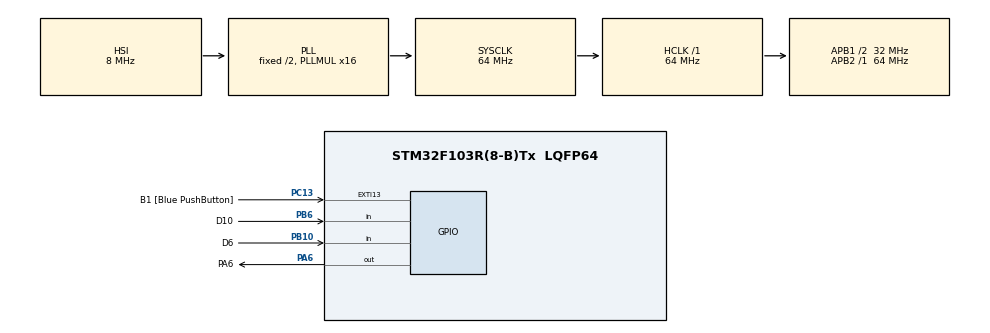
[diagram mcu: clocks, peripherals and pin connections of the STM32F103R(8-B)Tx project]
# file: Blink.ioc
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Mcu.Family=STM32F1
Mcu.Name=STM32F103R(8-B)Tx
Mcu.Package=LQFP64
NVIC.PriorityGroup=NVIC_PRIORITYGROUP_4
PA13.GPIO_Label=TMS
PA13.Mode=Serial_Wire
PA13.Signal=SYS_JTMS-SWDIO
PA14.GPIO_Label=TCK
PA14.Mode=Serial_Wire
PA14.Signal=SYS_JTCK-SWCLK
PA6.GPIO_Label=PA6
PA6.Signal=GPIO_Output
PB10.GPIO_Label=D6
PB10.GPIO_PuPd=GPIO_PULLDOWN
PB10.Signal=GPIO_Input
PB3.GPIO_Label=SWO
PB3.Signal=SYS_JTDO-TRACESWO
PB6.GPIO_Label=D10
PB6.GPIO_PuPd=GPIO_PULLDOWN
PB6.Signal=GPIO_Input
PC13-TAMPER-RTC.GPIO_Label=B1 [Blue PushButton]
PC13-TAMPER-RTC.GPIO_PuPd=GPIO_NOPULL
PC13-TAMPER-RTC.Signal=GPXTI13
PC14-OSC32_IN.Mode=LSE-External-Oscillator
PC14-OSC32_IN.Signal=RCC_OSC32_IN
PC15-OSC32_OUT.Mode=LSE-External-Oscillator
PC15-OSC32_OUT.Signal=RCC_OSC32_OUT
PD0-OSC_IN.Mode=HSE-External-Clock-Source
PD0-OSC_IN.Signal=RCC_OSC_IN
PD1-OSC_OUT.Mode=HSE-External-Clock-Source
PD1-OSC_OUT.Signal=RCC_OSC_OUT
ProjectManager.HeapSize=0x200
ProjectManager.StackSize=0x400
ProjectManager.TargetToolchain=STM32CubeIDE
RCC.AHBFreq_Value=64000000
RCC.APB1CLKDivider=RCC_HCLK_DIV2
RCC.APB1Freq_Value=32000000
RCC.APB1TimFreq_Value=64000000
RCC.APB2Freq_Value=64000000
RCC.APB2TimFreq_Value=64000000
RCC.HCLKFreq_Value=64000000
RCC.PLLMUL=RCC_PLL_MUL16
RCC.RTCClockSelection=RCC_RTCCLKSOURCE_LSE
RCC.SYSCLKFreq_VALUE=64000000
RCC.SYSCLKSource=RCC_SYSCLKSOURCE_PLLCLK
RCC.USBFreq_Value=64000000
board=NUCLEO-F103RB

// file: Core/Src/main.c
/* USER CODE BEGIN Header */
/**
 ******************************************************************************
 * @file           : main.c
 * @brief          : Main program body
 ******************************************************************************
 * @attention
 *
 * Copyright (c) 2026 STMicroelectronics.
 * All rights reserved.
 *
 * This software is licensed under terms that can be found in the LICENSE file
 * in the root directory of this software component.
 * If no LICENSE file comes with this software, it is provided AS-IS.
 *
 ******************************************************************************
 */
/**
 * 02_BlinkHAL  —  [계층: HAL]  CubeMX 생성 코드 + HAL API 로 GPIOA PA6 점멸
 *
 * 01_BlinkArduino -> 02_BlinkHAL -> 03_BlinkLL -> 04_BlinkReg 시리즈의 두 번째.
 * 사용자 코드는 main 루프의 두 줄(HAL_GPIO_TogglePin, HAL_Delay)뿐이고, 클록/GPIO 초기화는
 * CubeMX 가 만든 SystemClock_Config(), MX_GPIO_Init() 이 담당한다.
 *
 * 하드웨어 대응 (RM0008)
 *   HAL_GPIO_TogglePin : GPIOA 의 출력 데이터(ODR 비트 6) 반전 — 내부적으로 GPIOA_BSRR/ODR 사용
 *   HAL_Delay(50)      : SysTick 1ms ISR 이 증가시키는 uwTick 을 비교하는 방식
 *   MX_GPIO_Init       : RCC_APB2ENR(GPIOx 클록), GPIOA_CRL(PA6 출력) 설정
 *
 * ISR 과 콜백의 구분
 *   SysTick_Handler() (stm32f1xx_it.c, 진짜 ISR) -> HAL_IncTick() 으로 uwTick 증가.
 *   이 예제에는 HAL 콜백을 직접 구현한 곳이 없다.
 */
/* USER CODE END Header */
#include "main.h"

void SystemClock_Config(void);
static void MX_GPIO_Init(void);

int main(void)
{

  /* MCU Configuration--------------------------------------------------------*/

  /* Reset of all peripherals, Initializes the Flash interface and the Systick. */
  HAL_Init();

  /* Configure the system clock */
  SystemClock_Config();

  /* Initialize all configured peripherals */
  MX_GPIO_Init();

  /* Infinite loop */
	while (1) {

    /* USER CODE BEGIN 3 */
    HAL_GPIO_TogglePin (PA6_GPIO_Port, PA6_Pin);
    HAL_Delay (50);
	}
  /* USER CODE END 3 */
}

void SystemClock_Config(void)
{
  RCC_OscInitTypeDef RCC_OscInitStruct = {0};
  RCC_ClkInitTypeDef RCC_ClkInitStruct = {0};

  /** Initializes the RCC Oscillators according to the specified parameters
  * in the RCC_OscInitTypeDef structure.
  */
  RCC_OscInitStruct.OscillatorType = RCC_OSCILLATORTYPE_HSI;
  RCC_OscInitStruct.HSIState = RCC_HSI_ON;
  RCC_OscInitStruct.HSICalibrationValue = RCC_HSICALIBRATION_DEFAULT;
  RCC_OscInitStruct.PLL.PLLState = RCC_PLL_ON;
  RCC_OscInitStruct.PLL.PLLSource = RCC_PLLSOURCE_HSI_DIV2;
  RCC_OscInitStruct.PLL.PLLMUL = RCC_PLL_MUL16;
  if (HAL_RCC_OscConfig(&RCC_OscInitStruct) != HAL_OK)
  {
    Error_Handler();
  }

  /** Initializes the CPU, AHB and APB buses clocks
  */
  RCC_ClkInitStruct.ClockType = RCC_CLOCKTYPE_HCLK|RCC_CLOCKTYPE_SYSCLK
                              |RCC_CLOCKTYPE_PCLK1|RCC_CLOCKTYPE_PCLK2;
  RCC_ClkInitStruct.SYSCLKSource = RCC_SYSCLKSOURCE_PLLCLK;
  RCC_ClkInitStruct.AHBCLKDivider = RCC_SYSCLK_DIV1;
  RCC_ClkInitStruct.APB1CLKDivider = RCC_HCLK_DIV2;
  RCC_ClkInitStruct.APB2CLKDivider = RCC_HCLK_DIV1;

  if (HAL_RCC_ClockConfig(&RCC_ClkInitStruct, FLASH_LATENCY_2) != HAL_OK)
  {
    Error_Handler();
  }
}

static void MX_GPIO_Init(void)
{
  GPIO_InitTypeDef GPIO_InitStruct = {0};
  /* USER CODE BEGIN MX_GPIO_Init_1 */
  /* [HAL] 사용하지 않는 헤더 핀 D6(PB10), D10(PB6)을 풀다운 입력으로 고정한다.
   * - 리셋 상태는 플로팅 입력(GPIOx_CRL/CRH 리셋값 0x4444_4444, CNF=01 MODE=00)이라
   *   로직 분석기로 보면 누설/잡음 때문에 신호가 임의로 바뀌어 보인다.
   * - HAL_GPIO_Init(GPIO_MODE_INPUT, GPIO_PULLDOWN)은 다음을 설정한다.
   *     PB6 : GPIOB_CRL 비트 27:24 = CNF6=10, MODE6=00 (풀업/풀다운 입력)
   *     PB10: GPIOB_CRH 비트 11:8  = CNF10=10, MODE10=00
   *     그리고 GPIOB_BRR에 1을 써서 ODR 해당 비트=0 → 풀다운 선택 (RM0008 9.2.1~9.2.6)
   * - D1(PA2)은 설정하지 않는다(Reset_State). NUCLEO 기본 설정(SB62 OFF, SB13 ON)에서
   *   D1 헤더와 CN10-35는 PA2와 끊겨 있어 펌웨어 풀다운이 닿지 않는다(UM1724).
   *   PA2는 ST-LINK 가상 COM 포트 수신선에 연결되어 있으므로 풀다운을 걸면 안 된다.
   *   D1 헤더를 고정하려면 외부 풀다운 저항이나 GND 연결을 사용한다. */

  /* USER CODE END MX_GPIO_Init_1 */

  /* GPIO Ports Clock Enable */
  __HAL_RCC_GPIOC_CLK_ENABLE();
  __HAL_RCC_GPIOD_CLK_ENABLE();
  __HAL_RCC_GPIOA_CLK_ENABLE();
  __HAL_RCC_GPIOB_CLK_ENABLE();

  /*Configure GPIO pin Output Level */
  HAL_GPIO_WritePin(PA6_GPIO_Port, PA6_Pin, GPIO_PIN_RESET);

  /*Configure GPIO pin : B1_Pin */
  GPIO_InitStruct.Pin = B1_Pin;
  GPIO_InitStruct.Mode = GPIO_MODE_IT_RISING;
  GPIO_InitStruct.Pull = GPIO_NOPULL;
  HAL_GPIO_Init(B1_GPIO_Port, &GPIO_InitStruct);

  /*Configure GPIO pin : PA6_Pin */
  GPIO_InitStruct.Pin = PA6_Pin;
  GPIO_InitStruct.Mode = GPIO_MODE_OUTPUT_PP;
  GPIO_InitStruct.Pull = GPIO_NOPULL;
  GPIO_InitStruct.Speed = GPIO_SPEED_FREQ_LOW;
  HAL_GPIO_Init(PA6_GPIO_Port, &GPIO_InitStruct);

  /*Configure GPIO pins : D6_Pin D10_Pin */
  GPIO_InitStruct.Pin = D6_Pin|D10_Pin;
  GPIO_InitStruct.Mode = GPIO_MODE_INPUT;
  GPIO_InitStruct.Pull = GPIO_PULLDOWN;
  HAL_GPIO_Init(GPIOB, &GPIO_InitStruct);

}

void Error_Handler(void)
{
	__disable_irq();
	while (1) {
	}
}
